# S32K324_M7 register map
Vendor: NXP Semiconductors; File version: 1.1
CPU: CM7 r0p1, little endian, MPU, FPU, VTOR, 4 interrupt priority bits
Registers are 32-bit, read-write, reset 0x0 unless marked. A register's access mark holds for its fields unless they carry their own. Offsets are from the block's base; [hi:lo] are bit positions; {n}, {i} and the like mark numbered series; 'fields as' and 'values as' point back to an identical list.

## MDM_AP
Base 0x40250600
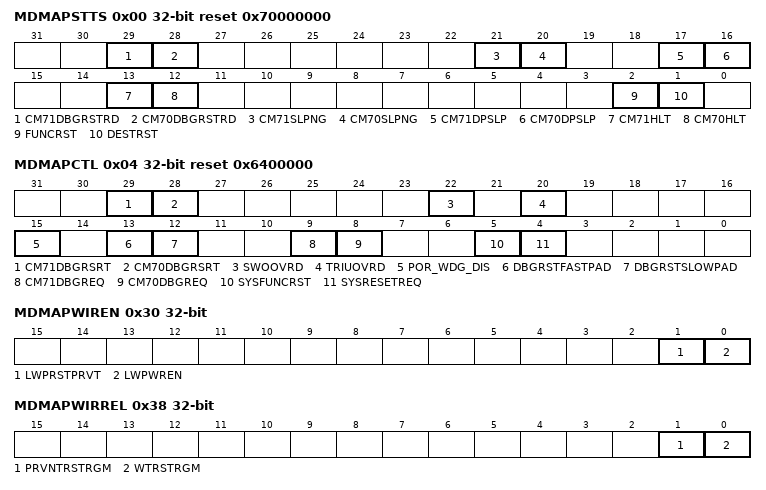
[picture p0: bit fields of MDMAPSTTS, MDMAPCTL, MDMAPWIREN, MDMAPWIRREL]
0x00 MDMAPSTTS ro reset 0x70000000 — Status
  [29] CM71DBGRSTRD — Cortex-M7_1 Debug Restarted
    0=In Debug mode; 1=In Normal mode
  [28] CM70DBGRSTRD — Cortex-M7_0 Debug Restarted
    0=In Debug mode; 1=In Normal mode
  [21] CM71SLPNG — CM7_1 Sleeping
    0=Not in Sleep mode; 1=In Sleep mode
  [20] CM70SLPNG — Cortex-M7_0 Sleeping
    0=Not in Sleep mode; 1=In Sleep mode
  [17] CM71DPSLP — Cortex-M7_1 Deep Sleep
    0=Not in Deep Sleep mode; 1=In Deep Sleep mode
  [16] CM70DPSLP — Cortex-M7_0 Deep Sleep
    0=Not in Deep Sleep mode; 1=In Deep Sleep mode
  [13] CM71HLT — CM7_1 Debug Halted
    0=Core is not halted; 1=Core is halted
  [12] CM70HLT — Cortex-M7_0 Halted
    0=Core is not halted; 1=Core is halted
  [2] FUNCRST — Functional Reset
    0=Not in functional reset; 1=In functional reset
  [1] DESTRST — Destructive Reset
    0=Not in destructive reset; 1=In destructive reset
0x04 MDMAPCTL reset 0x6400000 — Control
  [29] CM71DBGRSRT — Cortex-M7_1 Debug Restart
    0=Normal operation; 1=Request asserted
  [28] CM70DBGRSRT — Cortex-M7_0 Debug Restart
    0=Normal operation; 1=Request asserted
  [22] SWOOVRD — SWO Override
    0=Not overridden, and SWO generates the trace response; 1=Is overridden
  [20] TRIUOVRD — TPIU Override
    0=Not overridden, and TPIU generates the trace response; 1=Is overridden and asserted
  [15] POR_WDG_DIS — Power Watchdog Status
    0=Power watchdog is disabled; 1=Power watchdog is enabled
  [13] DBGRSTFASTPAD — Debug Over Reset Via Fast Pads
    0=Disabled; 1=Enabled
  [12] DBGRSTSLOWPAD — Debug Over Reset Via Slow Pads
    0=Disabled; 1=Enabled
  [9] CM71DBGREQ — Cortex-M7_1 Debug Request
    0=Debug request is not generated; 1=Debug request is generated
  [8] CM70DBGREQ — Cortex-M7_0 Debug Request
    values as CM71DBGREQ
  [5] SYSFUNCRST — System Functional Reset
    0=Deasserted; 1=Asserted
  [4] SYSRESETREQ — System Destructive Reset
    0=Deasserted; 1=Asserted
0x30 MDMAPWIREN — WIR Enable
  [1] LWPRSTPRVT — Low-Power Entry
    0=Prevents MC_RGM from generating the reset until the MC_RGM TPIU flush receives an acknowledgment from TPIU; 1=Prevents MC_RGM from generating the reset even if MC_RGM receives an acknowledgment from TPIU
  [0] LWPWREN — Low Power Debug Enable
    0=Disabled; 1=Enabled
0x34 MDMAPWIRSTTS ro — WIR Status
  [31:0] MDM_DAP_WIR_STATUS — MDM_AP WIR Status
0x38 MDMAPWIRREL — WIR Release
  [1] PRVNTRSTRGM — Prevent Reset
    0=Normal operation; 1=MC_RGM prevented
  [0] WTRSTRGM — Wait In Reset B
    0=Normal operation; 1=Wait supported
0xFC ID ro reset 0x1C0030 — Identity

## SDA_AP
Base 0x40254700
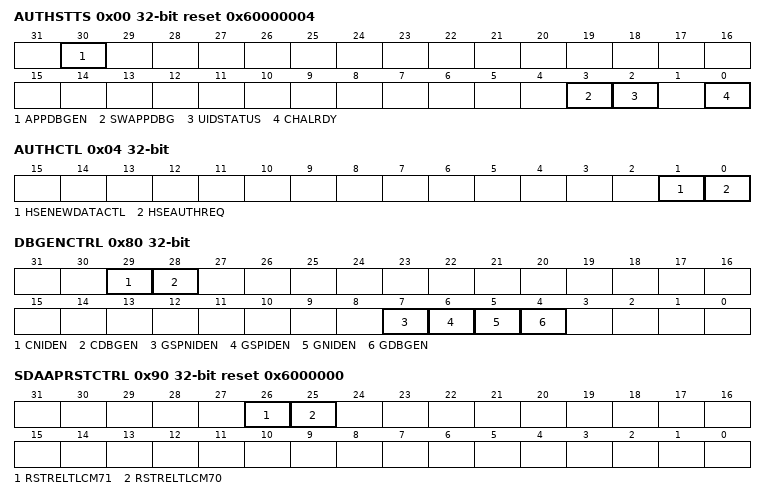
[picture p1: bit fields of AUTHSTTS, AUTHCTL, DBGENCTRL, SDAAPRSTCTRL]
0x00 AUTHSTTS ro reset 0x60000004 — Authentication Status
  [30] APPDBGEN — Application Debug Enabled or Disabled
    0=Application debug disabled; 1=Application debug enabled
  [3] SWAPPDBG — Software Application Debug
    0=Software application debug disabled; 1=Software application debug enabled
  [2] UIDSTATUS — User Identification Status
    0=UID is not ready and is invalid; 1=UID is ready and is valid
  [0] CHALRDY — Challenge Ready
    0=Challenge is not ready; 1=Challenge is ready
0x04 AUTHCTL — Authentication Control
  [1] HSENEWDATACTL — New Data Control
    0=Does not indicate that the debugger has consumed the data registers; 1=Indicates that the debugger has consumed the data registers
  [0] HSEAUTHREQ — Debug Enablement Authentication Request
    0=Does not start the authentication request; 1=Starts the authentication request
{0x10+4i} KEYCHAL[{i}] (i=0..7) ro — Key Challenge
  [31:0] KEYCHAL — Debug Enablement Key Challenge
{0x40+4i} KEYRESP[{i}] (i=0..7) — Key Response
  [31:0] KEYRESP — Debug Enablement Key Response
0x70 UID0 ro — User Identification 0
  [31:0] UID0 — User ID 0
0x74 UID1 ro — User Identification 1
  [31:0] UID1 — User ID 1
0x80 DBGENCTRL reset not defined — Debug Enable Control
  [all] fields
    0=Disabled; 1=Enabled
  [29] CNIDEN — Core Non-Invasive Debug Enable
  [28] CDBGEN — Core Debug Enable
  [7] GSPNIDEN — Global Secure Privileged Non-Invasive Debug Enable
  [6] GSPIDEN — Global Secure Privileged Debug Enable
  [5] GNIDEN — Global Non-Invasive Debug Enable
  [4] GDBGEN — Global Debug Enable
0x90 SDAAPRSTCTRL reset 0x6000000 — Reset Control
  [26] RSTRELTLCM71 — Reset Release Cortex-M7_1
    0=Core is in reset; 1=Reset is released
  [25] RSTRELTLCM70 — Reset Release Cortex-M7_0
    0=Core is in reset; 1=Reset is released
{0xA0+0x10*i} SDAAPGENSTATUS{i} ro (i=0..4) — SDA_AP Generic Status
  [31:0] SDAAPGENSTATUS — DAP Generic Status
0xA4 SDAAPGENCTRL0 — Generic Control 0
  [0] JTAG_CR_EN — JTAG CR Enable
    0=Function performed on the basis of SWJ-DP mode; 1=Function performed on the basis of JTAG mode
0xFC ID ro reset 0x1C0040 — Identity
